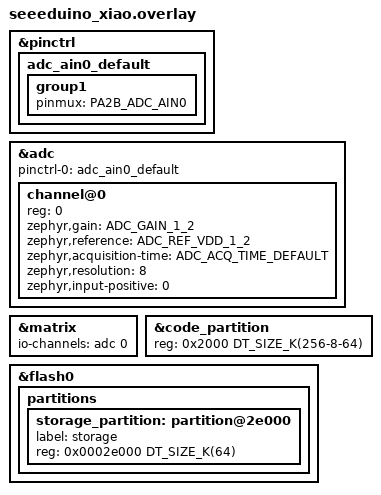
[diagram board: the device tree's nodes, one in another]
&pinctrl {
	adc_ain0_default: adc_ain0_default {
		group1 {
			pinmux = <PA2B_ADC_AIN0>;
		};
	};
};

&adc {
	pinctrl-0 = <&adc_ain0_default>;
	pinctrl-names = "default";
	status = "okay";
	#address-cells = <1>;
	#size-cells = <0>;

	channel@0 {
		reg = <0>;
		zephyr,gain = "ADC_GAIN_1_2";
		zephyr,reference = "ADC_REF_VDD_1_2";
		zephyr,acquisition-time = <ADC_ACQ_TIME_DEFAULT>;
		zephyr,resolution = <8>;
		zephyr,input-positive = <0>;
	};
};

&matrix {
	io-channels = <&adc 0>;
};

/delete-node/ &storage_partition;

&code_partition { 
	reg = <0x2000 DT_SIZE_K(256-8-64)>;
};

&flash0 {
	partitions {
		/*
		 * The final 16 KiB is reserved for the application.
		 * Storage partition may be used by FCB or LittleFS.
		 */
		storage_partition: partition@2e000 {
			label = "storage";
			reg = <0x0002e000 DT_SIZE_K(64)>;
		};
	};
};
